# LCM32F039 register map
File version: 1.0
CPU: CM0 r1p0, little endian, MPU, no FPU, 3 interrupt priority bits
Registers are 32-bit, read-write, reset 0x0 unless marked. A register's access mark holds for its fields unless they carry their own. Offsets are from the block's base; [hi:lo] are bit positions.

## TIM14 — General timer
Base 0x4000A000
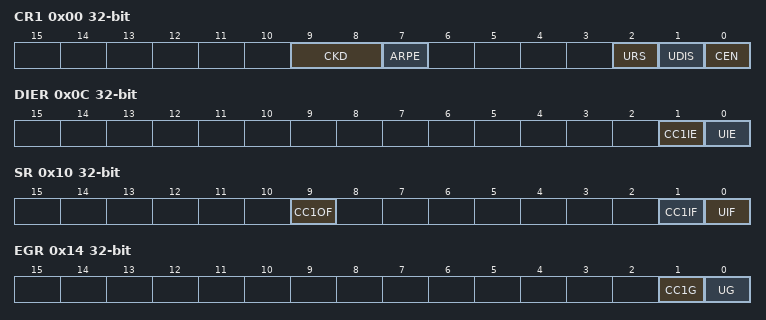
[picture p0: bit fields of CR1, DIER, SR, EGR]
0x00 CR1 — control register 1
  [9:8] CKD — Clock division
  [7] ARPE — Auto-reload preload enable
  [2] URS — Update request source
  [1] UDIS — Update disable
  [0] CEN — Counter enable
0x04 CR2 — control register 2
  [16] TrigS — Trigger select
0x0C DIER — DMA/Interrupt enable register
  [1] CC1IE — Capture/Compare 1 interrupt enable
  [0] UIE — Update interrupt enable
0x10 SR — status register
  [9] CC1OF — Capture/Compare 1 overcapture flag
  [1] CC1IF — Capture/compare 1 interrupt flag
  [0] UIF — Update interrupt flag
0x14 EGR read-write- — event generation register
  [1] CC1G — Capture/compare 1 generation
  [0] UG — Update generation
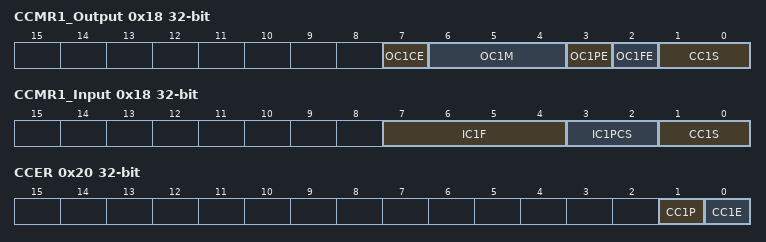
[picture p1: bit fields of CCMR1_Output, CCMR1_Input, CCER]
0x18 CCMR1_Output — capture/compare mode register (output mode)
  [7] OC1CE — Output Compare 1 clear enable
  [6:4] OC1M — Output Compare 1 mode
  [3] OC1PE — Output Compare 1 preload enable
  [2] OC1FE — Output Compare 1 fast enable
  [1:0] CC1S — Capture/Compare 1 selection
0x18 CCMR1_Input (alternate view of CCMR1_Output) — capture/compare mode register 1 (input mode)
  [7:4] IC1F — Input capture 1 filter
  [3:2] IC1PCS — Input capture 1 prescaler
  [1:0] CC1S — Capture/Compare 1 selection
0x20 CCER — capture/compare enable register
  [1] CC1P — Capture/Compare 1 output Polarity
  [0] CC1E — Capture/Compare 1 output enable
0x24 CNT — counter
  [15:0] CNT — counter value
0x28 PSC — prescaler
  [15:0] PSC — Prescaler value
0x2C ARR — auto-reload register
  [15:0] ARR — Auto-reload value
0x34 CCR1 — capture/compare register 1
  [15:0] CCR1 — Capture/Compare 1 value
0x50 OR — Option register
  [1:0] TI1_RMP — TIM1 mapping

## TIM16 — General timer
Base 0x4001C000
Same registers: TIM17 0x4001E000
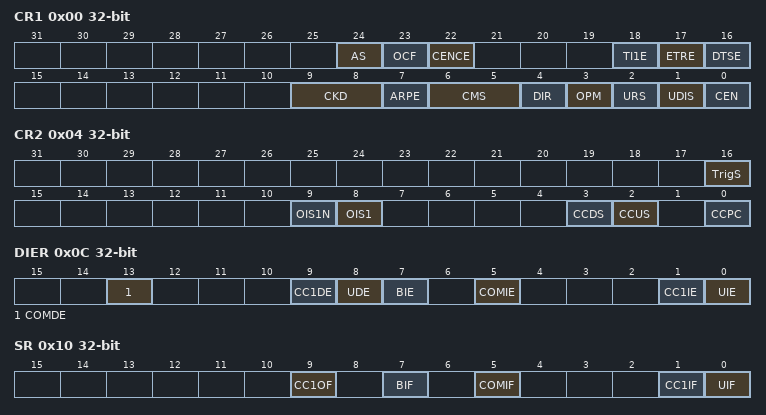
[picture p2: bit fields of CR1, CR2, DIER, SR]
0x00 CR1 — control register 1
  [24] AS — Active register selection for mcu read
  [23] OCF — OC/OCN asynchronous anti-glitch filter
  [22] CENCE — OCREF clear enable when CEN is disabled
  [18] TI1E — TI1 input detection/filter enable
  [17] ETRE — External trigger input detection/filter enable
  [16] DTSE — DTS clock enable
  [9:8] CKD — Clock division
  [7] ARPE — Auto-reload preload enable
  [6:5] CMS — Center-aligned modeselection
  [4] DIR — Direction
  [3] OPM — One-pulse mode
  [2] URS — Update request source
  [1] UDIS — Update disable
  [0] CEN — Counter enable
0x04 CR2 — control register 2
  [16] TrigS — Trigger select
  [9] OIS1N — Output Idle state 1
  [8] OIS1 — Output Idle state 1
  [3] CCDS — Capture/compare DMA selection
  [2] CCUS — Capture/compare control update selection
  [0] CCPC — Capture/compare preloaded control
0x0C DIER — DMA/Interrupt enable register
  [13] COMDE — COM DMA request enable
  [9] CC1DE — Capture/Compare 1 DMA request enable
  [8] UDE — Update DMA request enable
  [7] BIE — Break interrupt enable
  [5] COMIE — COM interrupt enable
  [1] CC1IE — Capture/Compare 1 interrupt enable
  [0] UIE — Update interrupt enable
0x10 SR — status register
  [9] CC1OF — Capture/Compare 1 overcapture flag
  [7] BIF — Break interrupt flag
  [5] COMIF — COM interrupt flag
  [1] CC1IF — Capture/compare 1 interrupt flag
  [0] UIF — Update interrupt flag
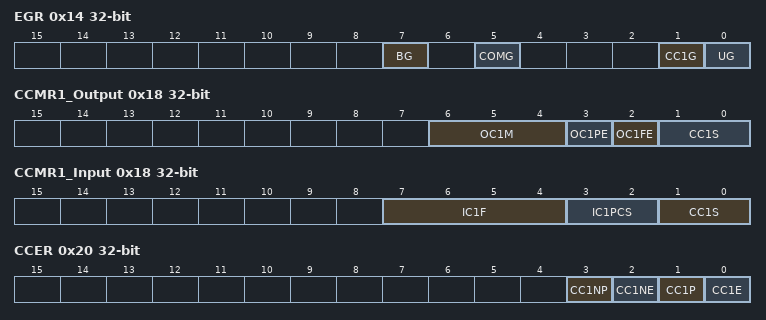
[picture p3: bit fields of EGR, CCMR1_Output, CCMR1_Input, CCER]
0x14 EGR — event generation register
  [7] BG — Break generation
  [5] COMG — Capture/Compare control update generation
  [1] CC1G — Capture/compare 1 generation
  [0] UG — Update generation
0x18 CCMR1_Output — capture/compare mode register (output mode)
  [6:4] OC1M — Output Compare 1 mode
  [3] OC1PE — Output Compare 1 preload enable
  [2] OC1FE — Output Compare 1 fast enable
  [1:0] CC1S — Capture/Compare 1 selection
0x18 CCMR1_Input (alternate view of CCMR1_Output) — capture/compare mode register 1 (input mode)
  [7:4] IC1F — Input capture 1 filter
  [3:2] IC1PCS — Input capture 1 prescaler
  [1:0] CC1S — Capture/Compare 1 selection
0x20 CCER — capture/compare enable register
  [3] CC1NP — Capture/Compare 1 output Polarity
  [2] CC1NE — Capture/Compare 1 complementary output enable
  [1] CC1P — Capture/Compare 1 output Polarity
  [0] CC1E — Capture/Compare 1 output enable
0x24 CNT — counter
  [15:0] CNT — counter value
0x28 PSC — prescaler
  [15:0] PSC — Prescaler value
0x2C ARR — auto-reload register
  [15:0] ARR — Auto-reload value
0x30 RCR — Repeat count register
  [7:0] REP — Repeat counter value
0x34 CCR1 — capture/compare register 1
  [15:0] CCR1 — Capture/Compare 1 value
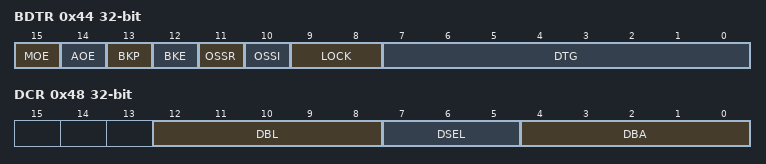
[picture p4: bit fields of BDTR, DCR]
0x44 BDTR — break and dead-time register
  [15] MOE — Main output enable
  [14] AOE — Automatic output enable
  [13] BKP — Break polarity
  [12] BKE — Break enable
  [11] OSSR — Off-state selection for Run mode
  [10] OSSI — Off-state selection for Idle mode
  [9:8] LOCK — Lock configuration
  [7:0] DTG — Dead-time generator setup
0x48 DCR — DMA control register
  [12:8] DBL — DMA burst length
  [7:5] DSEL — DSEL burst length
  [4:0] DBA — DMA base address
0x4C DMAR — DMA address for full transfer
  [15:0] DMAB — DMA register for burst accesses
